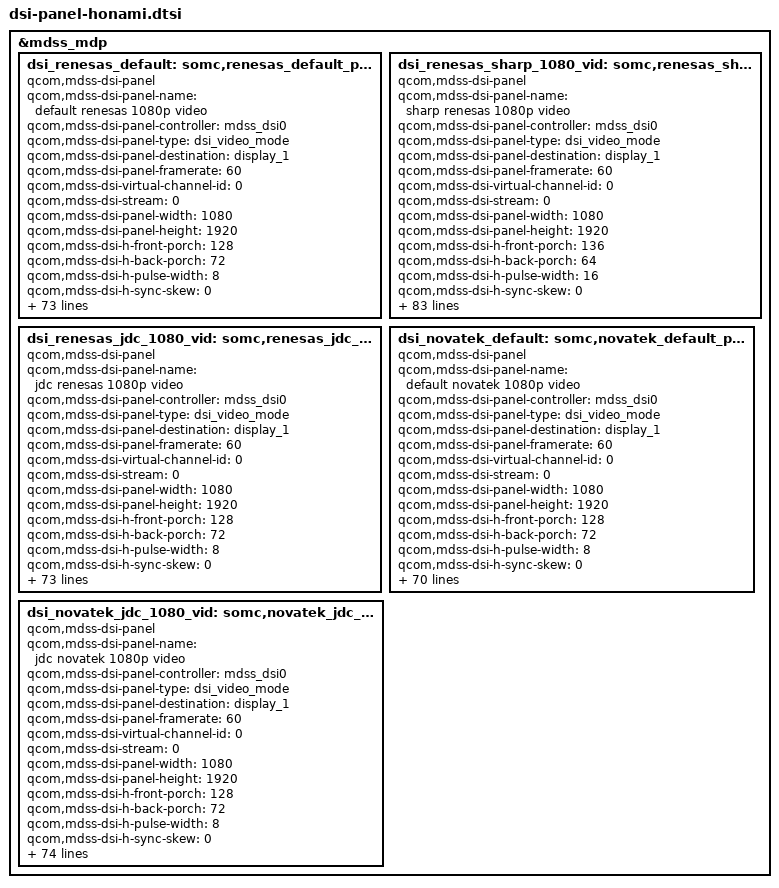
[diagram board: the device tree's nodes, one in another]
/* Copyright (c) 2012, Code Aurora Forum. All rights reserved.
 * Copyright (C) 2013-2014 Sony Mobile Communications AB.
 *
 * This program is free software; you can redistribute it and/or modify
 * it under the terms of the GNU General Public License version 2 and
 * only version 2 as published by the Free Software Foundation.
 *
 * This program is distributed in the hope that it will be useful,
 * but WITHOUT ANY WARRANTY; without even the implied warranty of
 * MERCHANTABILITY or FITNESS FOR A PARTICULAR PURPOSE.  See the
 * GNU General Public License for more details.
 */

&mdss_mdp {
	dsi_renesas_default: somc,renesas_default_panel {
		compatible = "qcom,mdss-dsi-panel";

		qcom,mdss-dsi-panel-name = "default renesas 1080p video";
		qcom,mdss-dsi-panel-controller = <&mdss_dsi0>;
		qcom,mdss-dsi-panel-type = "dsi_video_mode";
		qcom,mdss-dsi-panel-destination = "display_1";
		qcom,mdss-dsi-panel-framerate = <60>;
		qcom,mdss-dsi-virtual-channel-id = <0>;
		qcom,mdss-dsi-stream = <0>;
		qcom,mdss-dsi-panel-width = <1080>;
		qcom,mdss-dsi-panel-height = <1920>;
		qcom,mdss-dsi-h-front-porch = <128>;
		qcom,mdss-dsi-h-back-porch = <72>;
		qcom,mdss-dsi-h-pulse-width = <8>;
		qcom,mdss-dsi-h-sync-skew = <0>;
		qcom,mdss-dsi-v-back-porch = <4>;
		qcom,mdss-dsi-v-front-porch = <8>;
		qcom,mdss-dsi-v-pulse-width = <4>;
		qcom,mdss-dsi-h-left-border = <0>;
		qcom,mdss-dsi-h-right-border = <0>;
		qcom,mdss-dsi-v-top-border = <0>;
		qcom,mdss-dsi-v-bottom-border = <0>;
		qcom,mdss-dsi-bpp = <24>;
		qcom,mdss-dsi-underflow-color = <0x0>;
		qcom,mdss-dsi-border-color = <0>;
		somc,mdss-dsi-id-read-command = [06 01 00 01 05 00 02 A1 00];
		somc,mdss-dsi-init-command = [23 01 00 00 00 00 02 B0 00
				23 01 00 00 00 00 02 D6 01
				29 01 00 00 00 00 19 C7
					07 08 0B 12 22 3D 30 3D 52 54 68 78
					07 08 0B 12 22 3D 30 3D 52 54 68 78
				29 01 00 00 00 00 19 C8
					07 12 1A 25 32 45 33 3F 4F 50 5D 78
					07 12 1A 25 32 45 33 3F 4F 50 5D 78
				29 01 00 00 00 00 19 C9
					07 21 2B 33 3D 4C 35 40 51 53 5C 78
					07 21 2B 33 3D 4C 35 40 51 53 5C 78
				05 01 00 00 00 00 01 11];
		qcom,mdss-dsi-on-command = [05 01 00 00 00 00 01 29];
		qcom,mdss-dsi-off-command = [05 01 00 00 14 00 01 28
				05 01 00 00 50 00 01 10];
		qcom,mdss-dsi-on-command-state = "dsi_lp_mode";
		qcom,mdss-dsi-off-command-state = "dsi_hs_mode";

		somc,mdss-dsi-cabc-early-on-command = [39 01 00 00 00 00 03 51 0F FF
				15 01 00 00 00 00 02 53 24
				15 01 00 00 00 00 02 55 03];
		somc,mdss-dsi-cabc-early-on-v3-command = [39 01 00 00 00 00 03 51 0F FF
				15 01 00 00 00 00 02 53 24
				15 01 00 00 00 00 02 55 03];
		somc,mdss-dsi-cabc-late-off-command = [39 01 00 00 00 00 03 51 00 00
				15 01 00 00 00 00 02 55 00
				15 01 00 00 00 00 02 53 20];
		somc,mdss-dsi-cabc-deferred-on-command = [23 01 00 00 00 00 02 B0 00
				29 01 00 00 00 00 08 B9 00 3F 18 18 9F 1F 80
				29 01 00 00 00 00 08 BA 00 3F 04 40 9F 1F A8
				29 01 00 00 00 00 1A B8 18 80 18 18 CF 1F 00
					0C 0F 6C 0F 6C 0F 0C
					0F DA 6D FF FF 10 7D
					BC F7 FF FF
				23 01 00 00 00 00 02 B0 03];
		somc,mdss-dsi-cabc-deferred-on-v3-command = [23 01 00 00 00 00 02 B0 00
				29 01 00 00 00 00 08 B9 00 30 18 18 9F 1F 80
				29 01 00 00 00 00 08 BA 00 30 04 40 9F 1F CC
				29 01 00 00 00 00 1A B8 18 80 18 18 CF 1F 00
					0C 14 6C 14 6C 15 0C
					14 DA 6D FF FF 10 4D
					81 BB E7 FF
				23 01 00 00 00 00 02 B0 03];
		somc,mdss-dsi-cabc-enabled = <1>;

		qcom,mdss-dsi-h-sync-pulse = <1>;
		qcom,mdss-dsi-traffic-mode = "non_burst_sync_event";
		qcom,mdss-dsi-bllp-eof-power-mode;
		qcom,mdss-dsi-bllp-power-mode;
		qcom,mdss-dsi-lane-0-state;
		qcom,mdss-dsi-lane-1-state;
		qcom,mdss-dsi-lane-2-state;
		qcom,mdss-dsi-lane-3-state;
		qcom,mdss-dsi-panel-timings = [da 46 39 00 5f 56 3c 48 5d 03 04 00];
		qcom,mdss-dsi-t-clk-post = <0x20>;
		qcom,mdss-dsi-t-clk-pre = <0x2a>;
		qcom,mdss-dsi-bl-min-level = <1>;
		qcom,mdss-dsi-bl-max-level = <4095>;
		qcom,mdss-dsi-dma-trigger = "trigger_sw";
		qcom,mdss-dsi-mdp-trigger = "none";
		qcom,mdss-dsi-bl-pmic-control-type = "bl_ctrl_wled";
		qcom,mdss-dsi-pan-enable-dynamic-fps;
		qcom,mdss-dsi-pan-fps-update = "dfps_suspend_resume_mode";
		qcom,mdss-dsi-reset-sequence = <1 20>, <0 200>, <1 20>;

		somc,panel-id = [ff];
		somc,panel-detect = <1>;
		somc,driver-ic = <0>;
		somc,panel-id-read-cmds;
		somc,dsi-restart-hack;
		qcom,mdss-pan-physical-width-dimension = <62>;
		qcom,mdss-pan-physical-height-dimension = <110>;
		somc,mdss-phy-size-mm = <62 110>;
		somc,mdss-dsi-lane-config = [00 c2 45 00 00 00 00 01 75
				00 c2 45 00 00 00 00 01 75
				00 c2 45 00 00 00 00 01 75
				00 c2 45 00 00 00 00 01 75
				00 02 45 00 00 00 00 01 97];
		somc,mdss-dsi-disp-on-in-hs = <1>;
		somc,mdss-dsi-wait-time-before-on-cmd = <120>;
		qcom,mdss-brightness-max-level = <255>;
		somc,disp-en-off-pre = <10>;
		somc,disp-en-off-post = <10>;
		somc,disp-en-on-pre = <25>;
		somc,pw-on-rst-seq = <0 10>, <1 10>;
		somc,pw-off-rst-seq = <0 10>;
	};

	dsi_renesas_sharp_1080_vid: somc,renesas_sharp_1080p_panel {
		compatible = "qcom,mdss-dsi-panel";

		qcom,mdss-dsi-panel-name = "sharp renesas 1080p video";
		qcom,mdss-dsi-panel-controller = <&mdss_dsi0>;
		qcom,mdss-dsi-panel-type = "dsi_video_mode";
		qcom,mdss-dsi-panel-destination = "display_1";
		qcom,mdss-dsi-panel-framerate = <60>;
		qcom,mdss-dsi-virtual-channel-id = <0>;
		qcom,mdss-dsi-stream = <0>;
		qcom,mdss-dsi-panel-width = <1080>;
		qcom,mdss-dsi-panel-height = <1920>;
		qcom,mdss-dsi-h-front-porch = <136>;
		qcom,mdss-dsi-h-back-porch = <64>;
		qcom,mdss-dsi-h-pulse-width = <16>;
		qcom,mdss-dsi-h-sync-skew = <0>;
		qcom,mdss-dsi-v-back-porch = <3>;
		qcom,mdss-dsi-v-front-porch = <2>;
		qcom,mdss-dsi-v-pulse-width = <2>;
		qcom,mdss-dsi-h-left-border = <0>;
		qcom,mdss-dsi-h-right-border = <0>;
		qcom,mdss-dsi-v-top-border = <0>;
		qcom,mdss-dsi-v-bottom-border = <0>;
		qcom,mdss-dsi-bpp = <24>;
		qcom,mdss-dsi-underflow-color = <0x0>;
		qcom,mdss-dsi-border-color = <0>;
		somc,mdss-dsi-id-read-command = [06 01 00 01 05 00 02 A1 00];
		somc,mdss-dsi-init-command = [29 01 00 00 00 00 02 B0 04
				05 01 00 00 00 00 02 00 00
				05 01 00 00 00 00 02 00 00
				29 01 00 00 00 00 19 C7
					0F 13 17 1D 28 3C 2A 3E 4E 5E 6D 75
					0F 14 18 1E 2A 3E 2D 42 53 63 71 78
				29 01 00 00 00 00 19 C8
					20 23 26 2B 32 43 2D 3F 4F 5D 6C 75
					22 25 28 2D 34 46 30 43 54 62 70 78
				29 01 00 00 00 00 19 C9
					1A 22 27 2D 37 48 31 41 52 62 6F 75
					1B 23 28 2F 39 4B 35 46 57 66 73 78
				29 01 00 00 00 00 08 C2 30 F7 80 05 08 00 00
				29 01 00 00 00 00 02 D6 01
				05 01 00 00 00 00 01 11];
		qcom,mdss-dsi-on-command = [05 01 00 00 00 00 01 29];
		qcom,mdss-dsi-off-command = [05 01 00 00 14 00 01 28
				05 01 00 00 64 00 01 10];
		qcom,mdss-dsi-on-command-state = "dsi_lp_mode";
		qcom,mdss-dsi-off-command-state = "dsi_hs_mode";

		somc,mdss-dsi-cabc-early-on-command = [39 01 00 00 00 00 03 51 0F FF
				15 01 00 00 00 00 02 53 24
				15 01 00 00 00 00 02 55 03];
		somc,mdss-dsi-cabc-early-on-v3-command = [39 01 00 00 00 00 03 51 0F FF
				15 01 00 00 00 00 02 53 24
				15 01 00 00 00 00 02 55 03];
		somc,mdss-dsi-cabc-late-off-command = [39 01 00 00 00 00 03 51 00 00
				15 01 00 00 00 00 02 55 00
				15 01 00 00 00 00 02 53 20];
		somc,mdss-dsi-cabc-deferred-on-command = [23 01 00 00 00 00 02 B0 00
				29 01 00 00 00 00 08 B9 00 3F 18 18 9F 1F 80
				29 01 00 00 00 00 08 BA 00 3F 04 40 9F 1F A8
				29 01 00 00 00 00 1A B8 18 80 18 18 CF 1F 00
					0C 0F 6C 0F 6C 0F 0C
					0F DA 6D FF FF 10 7D
					BC F7 FF FF
				23 01 00 00 00 00 02 B0 03];
		somc,mdss-dsi-cabc-deferred-on-v3-command = [23 01 00 00 00 00 02 B0 00
				29 01 00 00 00 00 08 B9 00 30 18 18 9F 1F 80
				29 01 00 00 00 00 08 BA 00 30 04 40 9F 1F CC
				29 01 00 00 00 00 1A B8 18 80 18 18 CF 1F 00
					0C 14 6C 14 6C 15 0C
					14 DA 6D FF FF 10 4D
					81 BB E7 FF
				23 01 00 00 00 00 02 B0 03];
		somc,mdss-dsi-cabc-enabled = <1>;

		qcom,mdss-dsi-h-sync-pulse = <1>;
		qcom,mdss-dsi-traffic-mode = "non_burst_sync_event";
		qcom,mdss-dsi-bllp-eof-power-mode;
		qcom,mdss-dsi-bllp-power-mode;
		qcom,mdss-dsi-lane-0-state;
		qcom,mdss-dsi-lane-1-state;
		qcom,mdss-dsi-lane-2-state;
		qcom,mdss-dsi-lane-3-state;
		qcom,mdss-dsi-panel-timings = [EA 38 25 00 67 6F 29 3C 5D 03 04 00];
		qcom,mdss-dsi-t-clk-post = <0x03>;
		qcom,mdss-dsi-t-clk-pre = <0x31>;
		qcom,mdss-dsi-bl-min-level = <1>;
		qcom,mdss-dsi-bl-max-level = <4095>;
		qcom,mdss-dsi-dma-trigger = "trigger_sw";
		qcom,mdss-dsi-mdp-trigger = "none";
		qcom,mdss-dsi-bl-pmic-control-type = "bl_ctrl_wled";
		qcom,mdss-dsi-pan-enable-dynamic-fps;
		qcom,mdss-dsi-pan-fps-update = "dfps_suspend_resume_mode";
		qcom,mdss-dsi-reset-sequence = <1 20>, <0 200>, <1 20>;

		somc,panel-id = [ff ff ff 63];
		somc,driver-ic = <0>;
		qcom,mdss-pan-physical-width-dimension = <62>;
		qcom,mdss-pan-physical-height-dimension = <110>;
		somc,mdss-phy-size-mm = <62 110>;
		somc,mdss-dsi-lane-config = [00 c2 45 00 00 00 00 01 75
				00 c2 45 00 00 00 00 01 75
				00 c2 45 00 00 00 00 01 75
				00 c2 45 00 00 00 00 01 75
				00 02 45 00 00 00 00 01 97];
		somc,mdss-dsi-disp-on-in-hs = <1>;
		somc,mdss-dsi-wait-time-before-on-cmd = <150>;
		qcom,mdss-brightness-max-level = <255>;
		somc,disp-en-off-pre = <10>;
		somc,disp-en-off-post = <10>;
		somc,disp-en-on-pre = <25>;
		somc,pw-on-rst-seq = <0 10>, <1 10>;
		somc,pw-off-rst-seq = <0 10>;

		somc,mdss-dsi-pre-uv-command = [29 01 00 00 00 00 02 B0 04];
		somc,mdss-dsi-uv-command = [04 01 00 00 00 00 01 EF];
		somc,mdss-dsi-uv-param-type = <1>;
		somc,mdss-dsi-pcc-table-size = <73>;
		somc,mdss-dsi-pcc-table = <
				0x00 0x01 0x10 0x13 0x28 0x2B 0x8000 0x7400 0x8000
				0x00 0x02 0x14 0x17 0x28 0x2B 0x7a80 0x7400 0x7e00
				0x00 0x03 0x18 0x1B 0x28 0x2B 0x7480 0x7380 0x8000
				0x00 0x04 0x1C 0x1F 0x28 0x2B 0x7280 0x7380 0x8000
				0x00 0x05 0x20 0x23 0x28 0x2B 0x6e00 0x7400 0x8000
				0x00 0x06 0x0C 0x0F 0x24 0x27 0x7f80 0x7200 0x7c00
				0x00 0x07 0x10 0x13 0x24 0x27 0x8000 0x7400 0x7d80
				0x00 0x08 0x14 0x17 0x24 0x27 0x7d00 0x7700 0x7e00
				0x00 0x09 0x18 0x1B 0x24 0x27 0x7700 0x7600 0x8000
				0x00 0x0A 0x1C 0x1F 0x24 0x27 0x7380 0x7500 0x7c00
				0x00 0x0B 0x20 0x23 0x24 0x27 0x6f00 0x7500 0x7e80
				0x00 0x0C 0x0C 0x0F 0x20 0x23 0x7f80 0x7200 0x7900
				0x00 0x0D 0x10 0x13 0x20 0x23 0x8000 0x7400 0x7b00
				0x00 0x0E 0x14 0x17 0x20 0x23 0x7a80 0x7400 0x7b00
				0x00 0x0F 0x18 0x1B 0x20 0x23 0x7800 0x7700 0x7e80
				0x00 0x10 0x1C 0x1F 0x20 0x23 0x7780 0x7900 0x7f80
				0x00 0x11 0x20 0x23 0x20 0x23 0x7300 0x7900 0x7f00
				0x00 0x12 0x24 0x27 0x20 0x23 0x7100 0x7980 0x8000
				0x00 0x13 0x0C 0x0F 0x1C 0x1F 0x7f80 0x7200 0x7700
				0x00 0x14 0x10 0x13 0x1C 0x1F 0x7c00 0x7000 0x7580
				0x00 0x15 0x14 0x17 0x1C 0x1F 0x7f80 0x7900 0x7e00
				0x00 0x16 0x18 0x1B 0x1C 0x1F 0x7c00 0x7a00 0x7d80
				0x00 0x17 0x1C 0x1F 0x1C 0x1F 0x7900 0x7a00 0x7e00
				0x00 0x18 0x20 0x23 0x1C 0x1F 0x7600 0x7c80 0x8000
				0x00 0x19 0x24 0x27 0x1C 0x1F 0x7300 0x7c00 0x7e80
				0x00 0x1A 0x0C 0x0F 0x18 0x1B 0x8000 0x7200 0x7300
				0x00 0x1B 0x10 0x13 0x18 0x1B 0x7e80 0x7200 0x7500
				0x00 0x1C 0x14 0x17 0x18 0x1B 0x7f00 0x7900 0x7b80
				0x00 0x1D 0x18 0x1B 0x18 0x1B 0x7f00 0x7d00 0x7e00
				0x00 0x1E 0x1C 0x1F 0x18 0x1B 0x7d00 0x7d80 0x8000
				0x00 0x1F 0x20 0x23 0x18 0x1B 0x7900 0x7f00 0x8000
				0x00 0x20 0x24 0x27 0x18 0x1B 0x7780 0x8000 0x8000
				0x00 0x21 0x10 0x13 0x14 0x17 0x7f80 0x7380 0x7200
				0x00 0x22 0x14 0x17 0x14 0x17 0x7f00 0x7900 0x7900
				0x00 0x23 0x18 0x1B 0x14 0x17 0x7f00 0x7d00 0x7b80
				0xFF 0x00 0x1C 0x1F 0x14 0x17 0x8000 0x8000 0x8000
				0x00 0x24 0x20 0x23 0x14 0x17 0x7a00 0x8000 0x7e80
				0x00 0x25 0x24 0x27 0x14 0x17 0x7780 0x8000 0x7d80
				0x00 0x26 0x10 0x13 0x10 0x13 0x8000 0x7400 0x7000
				0x00 0x27 0x14 0x17 0x10 0x13 0x7f80 0x7900 0x7680
				0x00 0x28 0x18 0x1B 0x10 0x13 0x8000 0x7d80 0x7980
				0x00 0x29 0x1C 0x1F 0x10 0x13 0x8000 0x8000 0x7c00
				0x00 0x2A 0x20 0x23 0x10 0x13 0x7a00 0x8000 0x7c00
				0x00 0x2B 0x10 0x13 0x0C 0x0F 0x7f80 0x7480 0x6f00
				0x00 0x2C 0x14 0x17 0x0C 0x0F 0x7f80 0x7900 0x7400
				0x00 0x2D 0x18 0x1B 0x0C 0x0F 0x7f80 0x7d80 0x7680
				0x00 0x2E 0x1C 0x1F 0x0C 0x0F 0x7C00 0x7C00 0x8000
				0x01 0x00 0x00 0x09 0x32 0x3B 0x8000 0x6D00 0x8000
				0x02 0x00 0x0A 0x13 0x32 0x3B 0x7A00 0x7100 0x8000
				0x03 0x00 0x14 0x1D 0x32 0x3B 0x7400 0x7180 0x8000
				0x04 0x00 0x1E 0x27 0x32 0x3B 0x7100 0x7200 0x8000
				0x05 0x00 0x28 0x31 0x32 0x3B 0x6C80 0x7180 0x8000
				0x06 0x00 0x32 0x3B 0x32 0x3B 0x6680 0x7300 0x8000
				0x07 0x00 0x00 0x09 0x28 0x31 0x8000 0x6B80 0x7080
				0x08 0x00 0x0A 0x13 0x28 0x31 0x8000 0x7400 0x8000
				0x09 0x00 0x14 0x1D 0x28 0x31 0x7A00 0x7700 0x8000
				0x0A 0x00 0x1E 0x27 0x28 0x31 0x7600 0x7780 0x8000
				0x0B 0x00 0x28 0x31 0x28 0x31 0x6F80 0x7980 0x8000
				0x0C 0x00 0x32 0x3B 0x28 0x31 0x7080 0x7E80 0x8000
				0x0D 0x00 0x00 0x09 0x14 0x27 0x8000 0x6B00 0x6D00
				0x0E 0x00 0x0A 0x13 0x14 0x27 0x8000 0x7380 0x7480
				0xFF 0x00 0x14 0x27 0x14 0x27 0x8000 0x8000 0x8000
				0x10 0x00 0x28 0x31 0x14 0x27 0x7500 0x8000 0x7E80
				0x11 0x00 0x32 0x3B 0x14 0x27 0x7100 0x8000 0x7C80
				0x12 0x00 0x00 0x09 0x00 0x09 0x8000 0x6900 0x6500
				0x13 0x00 0x00 0x13 0x0A 0x13 0x8000 0x7300 0x6F00
				0x13 0x00 0x0A 0x13 0x00 0x09 0x8000 0x7300 0x6F00
				0x14 0x00 0x14 0x27 0x0A 0x13 0x7F00 0x8000 0x7900
				0x15 0x00 0x14 0x27 0x00 0x09 0x7E80 0x8000 0x7680
				0x16 0x00 0x28 0x31 0x0A 0x13 0x7380 0x8000 0x7600
				0x17 0x00 0x32 0x3B 0x0A 0x13 0x7080 0x8000 0x7900
				0x18 0x00 0x28 0x31 0x00 0x09 0x7A00 0x8000 0x7580
				0x19 0x00 0x32 0x3B 0x00 0x09 0x6F00 0x8000 0x7200>;
		somc,mdss-dsi-use-picadj = <1>;
		somc,mdss-dsi-picadj-sat = <6674>;
		somc,mdss-dsi-picadj-hue = <0>;
		somc,mdss-dsi-picadj-val = <0>;
		somc,mdss-dsi-picadj-cont = <9>;
	};

	dsi_renesas_jdc_1080_vid: somc,renesas_jdc_1080p_panel {
		compatible = "qcom,mdss-dsi-panel";

		qcom,mdss-dsi-panel-name = "jdc renesas 1080p video";
		qcom,mdss-dsi-panel-controller = <&mdss_dsi0>;
		qcom,mdss-dsi-panel-type = "dsi_video_mode";
		qcom,mdss-dsi-panel-destination = "display_1";
		qcom,mdss-dsi-panel-framerate = <60>;
		qcom,mdss-dsi-virtual-channel-id = <0>;
		qcom,mdss-dsi-stream = <0>;
		qcom,mdss-dsi-panel-width = <1080>;
		qcom,mdss-dsi-panel-height = <1920>;
		qcom,mdss-dsi-h-front-porch = <128>;
		qcom,mdss-dsi-h-back-porch = <72>;
		qcom,mdss-dsi-h-pulse-width = <8>;
		qcom,mdss-dsi-h-sync-skew = <0>;
		qcom,mdss-dsi-v-back-porch = <4>;
		qcom,mdss-dsi-v-front-porch = <8>;
		qcom,mdss-dsi-v-pulse-width = <4>;
		qcom,mdss-dsi-h-left-border = <0>;
		qcom,mdss-dsi-h-right-border = <0>;
		qcom,mdss-dsi-v-top-border = <0>;
		qcom,mdss-dsi-v-bottom-border = <0>;
		qcom,mdss-dsi-bpp = <24>;
		qcom,mdss-dsi-underflow-color = <0x0>;
		qcom,mdss-dsi-border-color = <0>;
		somc,mdss-dsi-id-read-command = [06 01 00 01 05 00 02 A1 00];
		somc,mdss-dsi-init-command = [23 01 00 00 00 00 02 B0 00
				23 01 00 00 00 00 02 D6 01
				29 01 00 00 00 00 19 C7
					07 08 0B 12 22 3D 30 3D 52 54 68 78
					07 08 0B 12 22 3D 30 3D 52 54 68 78
				29 01 00 00 00 00 19 C8
					07 12 1A 25 32 45 33 3F 4F 50 5D 78
					07 12 1A 25 32 45 33 3F 4F 50 5D 78
				29 01 00 00 00 00 19 C9
					07 21 2B 33 3D 4C 35 40 51 53 5C 78
					07 21 2B 33 3D 4C 35 40 51 53 5C 78
				05 01 00 00 00 00 01 11];
		qcom,mdss-dsi-on-command = [05 01 00 00 00 00 01 29];
		qcom,mdss-dsi-off-command = [05 01 00 00 14 00 01 28
				05 01 00 00 50 00 01 10];
		qcom,mdss-dsi-on-command-state = "dsi_lp_mode";
		qcom,mdss-dsi-off-command-state = "dsi_hs_mode";

		somc,mdss-dsi-cabc-early-on-command = [39 01 00 00 00 00 03 51 0F FF
				15 01 00 00 00 00 02 53 24
				15 01 00 00 00 00 02 55 03];
		somc,mdss-dsi-cabc-early-on-v3-command = [39 01 00 00 00 00 03 51 0F FF
				15 01 00 00 00 00 02 53 24
				15 01 00 00 00 00 02 55 03];
		somc,mdss-dsi-cabc-late-off-command = [39 01 00 00 00 00 03 51 00 00
				15 01 00 00 00 00 02 55 00
				15 01 00 00 00 00 02 53 20];
		somc,mdss-dsi-cabc-deferred-on-command = [23 01 00 00 00 00 02 B0 00
				29 01 00 00 00 00 08 B9 00 3F 18 18 9F 1F 80
				29 01 00 00 00 00 08 BA 00 3F 04 40 9F 1F A8
				29 01 00 00 00 00 1A B8 18 80 18 18 CF 1F 00
					0C 0F 6C 0F 6C 0F 0C
					0F DA 6D FF FF 10 7D
					BC F7 FF FF
				23 01 00 00 00 00 02 B0 03];
		somc,mdss-dsi-cabc-deferred-on-v3-command = [23 01 00 00 00 00 02 B0 00
				29 01 00 00 00 00 08 B9 00 30 18 18 9F 1F 80
				29 01 00 00 00 00 08 BA 00 30 04 40 9F 1F CC
				29 01 00 00 00 00 1A B8 18 80 18 18 CF 1F 00
					0C 14 6C 14 6C 15 0C
					14 DA 6D FF FF 10 4D
					81 BB E7 FF
				23 01 00 00 00 00 02 B0 03];
		somc,mdss-dsi-cabc-enabled = <1>;

		qcom,mdss-dsi-h-sync-pulse = <1>;
		qcom,mdss-dsi-traffic-mode = "non_burst_sync_event";
		qcom,mdss-dsi-bllp-eof-power-mode;
		qcom,mdss-dsi-bllp-power-mode;
		qcom,mdss-dsi-lane-0-state;
		qcom,mdss-dsi-lane-1-state;
		qcom,mdss-dsi-lane-2-state;
		qcom,mdss-dsi-lane-3-state;
		qcom,mdss-dsi-panel-timings = [da 46 39 00 5f 56 3c 48 5d 03 04 00];
		qcom,mdss-dsi-t-clk-post = <0x20>;
		qcom,mdss-dsi-t-clk-pre = <0x2a>;
		qcom,mdss-dsi-bl-min-level = <1>;
		qcom,mdss-dsi-bl-max-level = <4095>;
		qcom,mdss-dsi-dma-trigger = "trigger_sw";
		qcom,mdss-dsi-mdp-trigger = "none";
		qcom,mdss-dsi-bl-pmic-control-type = "bl_ctrl_wled";
		qcom,mdss-dsi-pan-enable-dynamic-fps;
		qcom,mdss-dsi-pan-fps-update = "dfps_suspend_resume_mode";
		qcom,mdss-dsi-reset-sequence = <1 20>, <0 200>, <1 20>;

		somc,panel-id = [ff ff ff 62];
		somc,driver-ic = <0>;
		qcom,mdss-pan-physical-width-dimension = <62>;
		qcom,mdss-pan-physical-height-dimension = <110>;
		somc,mdss-phy-size-mm = <62 110>;
		somc,mdss-dsi-lane-config = [00 c2 45 00 00 00 00 01 75
				00 c2 45 00 00 00 00 01 75
				00 c2 45 00 00 00 00 01 75
				00 c2 45 00 00 00 00 01 75
				00 02 45 00 00 00 00 01 97];
		somc,mdss-dsi-disp-on-in-hs = <1>;
		qcom,mdss-brightness-max-level = <255>;
		somc,mdss-dsi-wait-time-before-on-cmd = <120>;

		somc,mdss-dsi-pre-uv-command = [29 01 00 00 00 00 02 B0 04];
		somc,mdss-dsi-uv-command = [04 01 00 00 00 00 01 EF];
		somc,mdss-dsi-uv-param-type = <1>;
		somc,mdss-dsi-pcc-table-size = <78>;
		somc,mdss-dsi-pcc-table = <
				0x00 0x01 0x26 0x29 0x38 0x3C 0x5FA9 0x7760 0x8000
				0x00 0x02 0x22 0x25 0x34 0x37 0x67BF 0x7988 0x8000
				0x00 0x03 0x26 0x29 0x34 0x37 0x67BF 0x7988 0x8000
				0x00 0x04 0x1F 0x22 0x30 0x33 0x6CCC 0x7AE1 0x8000
				0x00 0x05 0x23 0x26 0x30 0x33 0x6CCC 0x7AE1 0x8000
				0x00 0x06 0x27 0x2A 0x30 0x33 0x6CCC 0x7AE1 0x8000
				0x00 0x07 0x1C 0x1F 0x2C 0x2F 0x79EF 0x7E62 0x8000
				0x00 0x08 0x20 0x23 0x2C 0x2F 0x79EF 0x7E62 0x8000
				0x00 0x09 0x24 0x27 0x2C 0x2F 0x79EF 0x7E62 0x8000
				0x00 0x0A 0x28 0x2B 0x2C 0x2F 0x79EF 0x7E62 0x8000
				0x00 0x0B 0x1A 0x1D 0x28 0x2B 0x8000 0x8000 0x8000
				0x00 0x0C 0x1E 0x21 0x28 0x2B 0x8000 0x8000 0x8000
				0x00 0x0D 0x22 0x25 0x28 0x2B 0x8000 0x8000 0x8000
				0x00 0x0E 0x26 0x29 0x28 0x2B 0x8000 0x8000 0x8000
				0x00 0x0F 0x18 0x1B 0x24 0x27 0x7f00 0x7880 0x8000
				0x00 0x10 0x1C 0x1F 0x24 0x27 0x7980 0x7900 0x8000
				0x00 0x11 0x20 0x23 0x24 0x27 0x7500 0x7980 0x8000
				0x00 0x12 0x24 0x27 0x24 0x27 0x7000 0x7a00 0x8000
				0x00 0x13 0x28 0x29 0x24 0x27 0x6d00 0x7a80 0x8000
				0x00 0x14 0x16 0x17 0x20 0x23 0x8000 0x7500 0x7900
				0x00 0x15 0x18 0x1B 0x20 0x23 0x8000 0x7900 0x7d00
				0x00 0x16 0x1C 0x1F 0x20 0x23 0x7c00 0x7b80 0x7f00
				0x00 0x17 0x20 0x23 0x20 0x23 0x7200 0x7780 0x7980
				0x00 0x18 0x24 0x27 0x20 0x23 0x7100 0x7c00 0x7e00
				0x00 0x19 0x28 0x29 0x20 0x23 0x6f00 0x7d80 0x7f00
				0x00 0x1A 0x16 0x17 0x1C 0x1F 0x8000 0x7500 0x7600
				0x00 0x1B 0x18 0x1B 0x1C 0x1F 0x8000 0x7980 0x7a00
				0xFF 0x00 0x1C 0x1F 0x1C 0x1F 0x8000 0x8000 0x8000
				0x00 0x1C 0x20 0x23 0x1C 0x1F 0x7900 0x8000 0x7e80
				0x00 0x1D 0x24 0x27 0x1C 0x1F 0x7400 0x8000 0x7e00
				0x00 0x1E 0x28 0x29 0x1C 0x1F 0x7000 0x8000 0x7d80
				0x00 0x1F 0x16 0x17 0x18 0x1B 0x8000 0x7500 0x7280
				0x00 0x20 0x18 0x1B 0x18 0x1B 0x8000 0x7a00 0x7600
				0x00 0x21 0x1C 0x1F 0x18 0x1B 0x7e80 0x8000 0x7b80
				0x00 0x22 0x20 0x23 0x18 0x1B 0x7900 0x8000 0x7b00
				0x00 0x23 0x24 0x27 0x18 0x1B 0x7400 0x8000 0x7a00
				0x00 0x24 0x28 0x29 0x18 0x1B 0x7000 0x8000 0x7a00
				0x00 0x25 0x16 0x19 0x14 0x17 0x8000 0x7780 0x7000
				0x00 0x26 0x1A 0x1D 0x14 0x17 0x8000 0x7e00 0x7500
				0x00 0x27 0x1E 0x21 0x14 0x17 0x7b00 0x8000 0x7500
				0x00 0x28 0x22 0x25 0x14 0x17 0x7580 0x8000 0x7600
				0x00 0x29 0x16 0x19 0x10 0x13 0x8000 0x7900 0x6c80
				0x00 0x2A 0x1A 0x1D 0x10 0x13 0x8000 0x7f00 0x7200
				0x00 0x2B 0x1E 0x21 0x10 0x13 0x7a00 0x8000 0x7180
				0x00 0x2C 0x22 0x25 0x10 0x13 0x7500 0x8000 0x7200
				0x00 0x2D 0x16 0x19 0x0C 0x0F 0x8000 0x7900 0x6a00
				0x00 0x2E 0x1A 0x1D 0x0C 0x0F 0x8000 0x8000 0x6f00
				0x00 0x2F 0x1E 0x21 0x0C 0x0F 0x7980 0x8000 0x6e00
				0x00 0x30 0x16 0x19 0x08 0x0B 0x8000 0x7900 0x6800
				0x00 0x31 0x1A 0x1D 0x08 0x0B 0x8000 0x8000 0x6c00
				0x00 0x32 0x16 0x19 0x04 0x07 0x8000 0x7880 0x6580
				0x00 0x33 0x26 0x29 0x14 0x17 0x7580 0x8000 0x7600
				0x01 0x00 0x00 0x09 0x32 0x3C 0x8000 0x6D00 0x8000
				0x02 0x00 0x0A 0x13 0x32 0x3C 0x7A00 0x7100 0x8000
				0x03 0x00 0x14 0x1D 0x32 0x3C 0x7400 0x7180 0x8000
				0x04 0x00 0x1E 0x27 0x32 0x3C 0x7100 0x7200 0x8000
				0x05 0x00 0x28 0x31 0x32 0x3C 0x6C80 0x7180 0x8000
				0x06 0x00 0x32 0x3C 0x32 0x3C 0x6680 0x7300 0x8000
				0x07 0x00 0x00 0x09 0x28 0x31 0x8000 0x6B80 0x7080
				0x08 0x00 0x0A 0x13 0x28 0x31 0x8000 0x7400 0x8000
				0x09 0x00 0x14 0x1D 0x28 0x31 0x7A00 0x7700 0x8000
				0x0A 0x00 0x1E 0x27 0x28 0x31 0x7600 0x7780 0x8000
				0x0B 0x00 0x28 0x31 0x28 0x31 0x6F80 0x7980 0x8000
				0x0C 0x00 0x32 0x3C 0x28 0x31 0x7080 0x7E80 0x8000
				0x0D 0x00 0x00 0x09 0x14 0x27 0x8000 0x6B00 0x6D00
				0x0E 0x00 0x0A 0x13 0x14 0x27 0x8000 0x7380 0x7480
				0xFF 0x00 0x14 0x27 0x14 0x27 0x8000 0x8000 0x8000
				0x10 0x00 0x28 0x31 0x14 0x27 0x7500 0x8000 0x7E80
				0x11 0x00 0x32 0x3C 0x14 0x27 0x7100 0x8000 0x7C80
				0x12 0x00 0x00 0x09 0x00 0x09 0x8000 0x6900 0x6500
				0x13 0x00 0x00 0x13 0x0A 0x13 0x8000 0x7300 0x6F00
				0x13 0x00 0x0A 0x13 0x00 0x09 0x8000 0x7300 0x6F00
				0x14 0x00 0x14 0x27 0x0A 0x13 0x7F00 0x8000 0x7900
				0x15 0x00 0x14 0x27 0x00 0x09 0x7E80 0x8000 0x7680
				0x16 0x00 0x28 0x31 0x0A 0x13 0x7380 0x8000 0x7600
				0x17 0x00 0x32 0x3C 0x0A 0x13 0x7080 0x8000 0x7900
				0x18 0x00 0x28 0x31 0x00 0x09 0x7A00 0x8000 0x7580
				0x19 0x00 0x32 0x3C 0x00 0x09 0x6F00 0x8000 0x7200>;
	};

	dsi_novatek_default: somc,novatek_default_panel {
		compatible = "qcom,mdss-dsi-panel";

		qcom,mdss-dsi-panel-name = "default novatek 1080p video";
		qcom,mdss-dsi-panel-controller = <&mdss_dsi0>;
		qcom,mdss-dsi-panel-type = "dsi_video_mode";
		qcom,mdss-dsi-panel-destination = "display_1";
		qcom,mdss-dsi-panel-framerate = <60>;
		qcom,mdss-dsi-virtual-channel-id = <0>;
		qcom,mdss-dsi-stream = <0>;
		qcom,mdss-dsi-panel-width = <1080>;
		qcom,mdss-dsi-panel-height = <1920>;
		qcom,mdss-dsi-h-front-porch = <128>;
		qcom,mdss-dsi-h-back-porch = <72>;
		qcom,mdss-dsi-h-pulse-width = <8>;
		qcom,mdss-dsi-h-sync-skew = <0>;
		qcom,mdss-dsi-v-back-porch = <4>;
		qcom,mdss-dsi-v-front-porch = <8>;
		qcom,mdss-dsi-v-pulse-width = <4>;
		qcom,mdss-dsi-h-left-border = <0>;
		qcom,mdss-dsi-h-right-border = <0>;
		qcom,mdss-dsi-v-top-border = <0>;
		qcom,mdss-dsi-v-bottom-border = <0>;
		qcom,mdss-dsi-bpp = <24>;
		qcom,mdss-dsi-underflow-color = <0x0>;
		qcom,mdss-dsi-border-color = <0>;
		somc,mdss-dsi-id-read-command = [06 01 00 01 05 00 02 A1 00];
		somc,mdss-dsi-init-command = [
				15 01 00 00 00 00 02 36 00
				15 01 00 00 00 00 02 D3 08
				15 01 00 00 00 00 02 D4 08
				15 01 00 00 00 00 02 D5 50
				15 01 00 00 00 00 02 D6 81
				13 01 00 00 00 00 02 FF 01
				13 01 00 00 00 00 02 FB 01
				13 01 00 00 00 00 02 75 00
				13 01 00 00 00 00 02 76 00
				13 01 00 00 00 00 02 77 00
				13 01 00 00 00 00 02 78 03
				13 01 00 00 00 00 02 79 00
				13 01 00 00 00 00 02 7A 0A
				13 01 00 00 00 00 02 7B 00
				13 01 00 00 00 00 02 7C 13
				13 01 00 00 00 00 02 7D 00
				13 01 00 00 00 00 02 7E 20
				13 01 00 00 00 00 02 7F 00
				13 01 00 00 00 00 02 80 2E
				13 01 00 00 00 00 02 81 00
				13 01 00 00 00 00 02 82 3C
				13 01 00 00 00 00 02 83 00
				13 01 00 00 00 00 02 84 47
				13 01 00 00 00 00 02 85 00
				13 01 00 00 00 00 02 86 52
				13 01 00 00 00 00 02 87 00
				13 01 00 00 00 00 02 88 8E
				13 01 00 00 00 00 02 89 00
				13 01 00 00 00 00 02 8A B8
				13 01 00 00 00 00 02 8B 01
				13 01 00 00 00 00 02 8C 01
				13 01 00 00 00 00 02 8D 01
				13 01 00 00 00 00 02 8E 3A
				13 01 00 00 00 00 02 8F 01
				13 01 00 00 00 00 02 90 7E
				13 01 00 00 00 00 02 91 01
				13 01 00 00 00 00 02 92 B2
				13 01 00 00 00 00 02 93 01
				13 01 00 00 00 00 02 94 B4
				13 01 00 00 00 00 02 95 01
				13 01 00 00 00 00 02 96 E8
				13 01 00 00 00 00 02 97 02
				13 01 00 00 00 00 02 98 18
				13 01 00 00 00 00 02 99 02
				13 01 00 00 00 00 02 9A 36
				13 01 00 00 00 00 02 9B 02
				13 01 00 00 00 00 02 9C 5C
				13 01 00 00 00 00 02 9D 02
				13 01 00 00 00 00 02 9E 93
				13 01 00 00 00 00 02 9F 02
				13 01 00 00 00 00 02 A0 E1
				13 01 00 00 00 00 02 A2 02
				13 01 00 00 00 00 02 A3 E4
				13 01 00 00 00 00 02 A4 02
				13 01 00 00 00 00 02 A5 E8
				13 01 00 00 00 00 02 A6 02
				13 01 00 00 00 00 02 A7 EC
				13 01 00 00 00 00 02 A9 03
				13 01 00 00 00 00 02 AA 09
				13 01 00 00 00 00 02 AB 03
				13 01 00 00 00 00 02 AC 49
				13 01 00 00 00 00 02 AD 03
				13 01 00 00 00 00 02 AE 81
				13 01 00 00 00 00 02 AF 03
				13 01 00 00 00 00 02 B0 B4
				13 01 00 00 00 00 02 B1 03
				13 01 00 00 00 00 02 B2 D3
				13 01 00 00 00 00 02 B3 00
				13 01 00 00 00 00 02 B4 00
				13 01 00 00 00 00 02 B5 00
				13 01 00 00 00 00 02 B6 03
				13 01 00 00 00 00 02 B7 00
				13 01 00 00 00 00 02 B8 0A
				13 01 00 00 00 00 02 B9 00
				13 01 00 00 00 00 02 BA 13
				13 01 00 00 00 00 02 BB 00
				13 01 00 00 00 00 02 BC 20
				13 01 00 00 00 00 02 BD 00
				13 01 00 00 00 00 02 BE 2E
				13 01 00 00 00 00 02 BF 00
				13 01 00 00 00 00 02 C0 3C
				13 01 00 00 00 00 02 C1 00
				13 01 00 00 00 00 02 C2 47
				13 01 00 00 00 00 02 C3 00
				13 01 00 00 00 00 02 C4 52
				13 01 00 00 00 00 02 C5 00
				13 01 00 00 00 00 02 C6 8E
				13 01 00 00 00 00 02 C7 00
				13 01 00 00 00 00 02 C8 B8
				13 01 00 00 00 00 02 C9 01
				13 01 00 00 00 00 02 CA 01
				13 01 00 00 00 00 02 CB 01
				13 01 00 00 00 00 02 CC 3A
				13 01 00 00 00 00 02 CD 01
				13 01 00 00 00 00 02 CE 7E
				13 01 00 00 00 00 02 CF 01
				13 01 00 00 00 00 02 D0 B2
				13 01 00 00 00 00 02 D1 01
				13 01 00 00 00 00 02 D2 B4
				13 01 00 00 00 00 02 D3 01
				13 01 00 00 00 00 02 D4 E8
				13 01 00 00 00 00 02 D5 02
				13 01 00 00 00 00 02 D6 18
				13 01 00 00 00 00 02 D7 02
				13 01 00 00 00 00 02 D8 36
				13 01 00 00 00 00 02 D9 02
				13 01 00 00 00 00 02 DA 5C
				13 01 00 00 00 00 02 DB 02
				13 01 00 00 00 00 02 DC 93
				13 01 00 00 00 00 02 DD 02
				13 01 00 00 00 00 02 DE E1
				13 01 00 00 00 00 02 DF 02
				13 01 00 00 00 00 02 E0 E4
				13 01 00 00 00 00 02 E1 02
				13 01 00 00 00 00 02 E2 E8
				13 01 00 00 00 00 02 E3 02
				13 01 00 00 00 00 02 E4 EC
				13 01 00 00 00 00 02 E5 03
				13 01 00 00 00 00 02 E6 09
				13 01 00 00 00 00 02 E7 03
				13 01 00 00 00 00 02 E8 49
				13 01 00 00 00 00 02 E9 03
				13 01 00 00 00 00 02 EA 81
				13 01 00 00 00 00 02 EB 03
				13 01 00 00 00 00 02 EC B4
				13 01 00 00 00 00 02 ED 03
				13 01 00 00 00 00 02 EE D3
				13 01 00 00 00 00 02 EF 00
				13 01 00 00 00 00 02 F0 00
				13 01 00 00 00 00 02 F1 00
				13 01 00 00 00 00 02 F2 17
				13 01 00 00 00 00 02 F3 00
				13 01 00 00 00 00 02 F4 3D
				13 01 00 00 00 00 02 F5 00
				13 01 00 00 00 00 02 F6 5C
				13 01 00 00 00 00 02 F7 00
				13 01 00 00 00 00 02 F8 79
				13 01 00 00 00 00 02 F9 00
				13 01 00 00 00 00 02 FA 92
				13 01 00 00 00 00 02 FF 02
				13 01 00 00 00 00 02 FB 01
				13 01 00 00 00 00 02 00 00
				13 01 00 00 00 00 02 01 A8
				13 01 00 00 00 00 02 02 00
				13 01 00 00 00 00 02 03 B9
				13 01 00 00 00 00 02 04 00
				13 01 00 00 00 00 02 05 CB
				13 01 00 00 00 00 02 06 00
				13 01 00 00 00 00 02 07 FF
				13 01 00 00 00 00 02 08 01
				13 01 00 00 00 00 02 09 24
				13 01 00 00 00 00 02 0A 01
				13 01 00 00 00 00 02 0B 55
				13 01 00 00 00 00 02 0C 01
				13 01 00 00 00 00 02 0D 7B
				13 01 00 00 00 00 02 0E 01
				13 01 00 00 00 00 02 0F AB
				13 01 00 00 00 00 02 10 01
				13 01 00 00 00 00 02 11 D6
				13 01 00 00 00 00 02 12 01
				13 01 00 00 00 00 02 13 D7
				13 01 00 00 00 00 02 14 02
				13 01 00 00 00 00 02 15 01
				13 01 00 00 00 00 02 16 02
				13 01 00 00 00 00 02 17 2A
				13 01 00 00 00 00 02 18 02
				13 01 00 00 00 00 02 19 45
				13 01 00 00 00 00 02 1A 02
				13 01 00 00 00 00 02 1B 68
				13 01 00 00 00 00 02 1C 02
				13 01 00 00 00 00 02 1D 92
				13 01 00 00 00 00 02 1E 02
				13 01 00 00 00 00 02 1F CE
				13 01 00 00 00 00 02 20 02
				13 01 00 00 00 00 02 21 D0
				13 01 00 00 00 00 02 22 02
				13 01 00 00 00 00 02 23 D1
				13 01 00 00 00 00 02 24 02
				13 01 00 00 00 00 02 25 D3
				13 01 00 00 00 00 02 26 02
				13 01 00 00 00 00 02 27 E6
				13 01 00 00 00 00 02 28 03
				13 01 00 00 00 00 02 29 10
				13 01 00 00 00 00 02 2A 03
				13 01 00 00 00 00 02 2B 48
				13 01 00 00 00 00 02 2D 03
				13 01 00 00 00 00 02 2F 9E
				13 01 00 00 00 00 02 30 03
				13 01 00 00 00 00 02 31 D3
				13 01 00 00 00 00 02 32 00
				13 01 00 00 00 00 02 33 00
				13 01 00 00 00 00 02 34 00
				13 01 00 00 00 00 02 35 17
				13 01 00 00 00 00 02 36 00
				13 01 00 00 00 00 02 37 3D
				13 01 00 00 00 00 02 38 00
				13 01 00 00 00 00 02 39 5C
				13 01 00 00 00 00 02 3A 00
				13 01 00 00 00 00 02 3B 79
				13 01 00 00 00 00 02 3D 00
				13 01 00 00 00 00 02 3F 92
				13 01 00 00 00 00 02 40 00
				13 01 00 00 00 00 02 41 A8
				13 01 00 00 00 00 02 42 00
				13 01 00 00 00 00 02 43 B9
				13 01 00 00 00 00 02 44 00
				13 01 00 00 00 00 02 45 CB
				13 01 00 00 00 00 02 46 00
				13 01 00 00 00 00 02 47 FF
				13 01 00 00 00 00 02 48 01
				13 01 00 00 00 00 02 49 24
				13 01 00 00 00 00 02 4A 01
				13 01 00 00 00 00 02 4B 55
				13 01 00 00 00 00 02 4C 01
				13 01 00 00 00 00 02 4D 7B
				13 01 00 00 00 00 02 4E 01
				13 01 00 00 00 00 02 4F AB
				13 01 00 00 00 00 02 50 01
				13 01 00 00 00 00 02 51 D6
				13 01 00 00 00 00 02 52 01
				13 01 00 00 00 00 02 53 D7
				13 01 00 00 00 00 02 54 02
				13 01 00 00 00 00 02 55 01
				13 01 00 00 00 00 02 56 02
				13 01 00 00 00 00 02 58 2A
				13 01 00 00 00 00 02 59 02
				13 01 00 00 00 00 02 5A 45
				13 01 00 00 00 00 02 5B 02
				13 01 00 00 00 00 02 5C 68
				13 01 00 00 00 00 02 5D 02
				13 01 00 00 00 00 02 5E 92
				13 01 00 00 00 00 02 5F 02
				13 01 00 00 00 00 02 60 CE
				13 01 00 00 00 00 02 61 02
				13 01 00 00 00 00 02 62 D0
				13 01 00 00 00 00 02 63 02
				13 01 00 00 00 00 02 64 D1
				13 01 00 00 00 00 02 65 02
				13 01 00 00 00 00 02 66 D3
				13 01 00 00 00 00 02 67 02
				13 01 00 00 00 00 02 68 E6
				13 01 00 00 00 00 02 69 03
				13 01 00 00 00 00 02 6A 10
				13 01 00 00 00 00 02 6B 03
				13 01 00 00 00 00 02 6C 48
				13 01 00 00 00 00 02 6D 03
				13 01 00 00 00 00 02 6E 9E
				13 01 00 00 00 00 02 6F 03
				13 01 00 00 00 00 02 70 D3
				13 01 00 00 00 00 02 71 00
				13 01 00 00 00 00 02 72 00
				13 01 00 00 00 00 02 73 00
				13 01 00 00 00 00 02 74 34
				13 01 00 00 00 00 02 75 00
				13 01 00 00 00 00 02 76 8A
				13 01 00 00 00 00 02 77 00
				13 01 00 00 00 00 02 78 BF
				13 01 00 00 00 00 02 79 00
				13 01 00 00 00 00 02 7A E2
				13 01 00 00 00 00 02 7B 00
				13 01 00 00 00 00 02 7C FB
				13 01 00 00 00 00 02 7D 01
				13 01 00 00 00 00 02 7E 0B
				13 01 00 00 00 00 02 7F 01
				13 01 00 00 00 00 02 80 17
				13 01 00 00 00 00 02 81 01
				13 01 00 00 00 00 02 82 24
				13 01 00 00 00 00 02 83 01
				13 01 00 00 00 00 02 84 4A
				13 01 00 00 00 00 02 85 01
				13 01 00 00 00 00 02 86 64
				13 01 00 00 00 00 02 87 01
				13 01 00 00 00 00 02 88 8C
				13 01 00 00 00 00 02 89 01
				13 01 00 00 00 00 02 8A AC
				13 01 00 00 00 00 02 8B 01
				13 01 00 00 00 00 02 8C D4
				13 01 00 00 00 00 02 8D 01
				13 01 00 00 00 00 02 8E F5
				13 01 00 00 00 00 02 8F 01
				13 01 00 00 00 00 02 90 F6
				13 01 00 00 00 00 02 91 02
				13 01 00 00 00 00 02 92 18
				13 01 00 00 00 00 02 93 02
				13 01 00 00 00 00 02 94 3B
				13 01 00 00 00 00 02 95 02
				13 01 00 00 00 00 02 96 55
				13 01 00 00 00 00 02 97 02
				13 01 00 00 00 00 02 98 75
				13 01 00 00 00 00 02 99 02
				13 01 00 00 00 00 02 9A 9F
				13 01 00 00 00 00 02 9B 02
				13 01 00 00 00 00 02 9C DB
				13 01 00 00 00 00 02 9D 02
				13 01 00 00 00 00 02 9E DE
				13 01 00 00 00 00 02 9F 02
				13 01 00 00 00 00 02 A0 E1
				13 01 00 00 00 00 02 A2 02
				13 01 00 00 00 00 02 A3 E5
				13 01 00 00 00 00 02 A4 02
				13 01 00 00 00 00 02 A5 F4
				13 01 00 00 00 00 02 A6 03
				13 01 00 00 00 00 02 A7 11
				13 01 00 00 00 00 02 A9 03
				13 01 00 00 00 00 02 AA 43
				13 01 00 00 00 00 02 AB 03
				13 01 00 00 00 00 02 AC 9C
				13 01 00 00 00 00 02 AD 03
				13 01 00 00 00 00 02 AE D3
				13 01 00 00 00 00 02 AF 00
				13 01 00 00 00 00 02 B0 00
				13 01 00 00 00 00 02 B1 00
				13 01 00 00 00 00 02 B2 34
				13 01 00 00 00 00 02 B3 00
				13 01 00 00 00 00 02 B4 8A
				13 01 00 00 00 00 02 B5 00
				13 01 00 00 00 00 02 B6 BF
				13 01 00 00 00 00 02 B7 00
				13 01 00 00 00 00 02 B8 E2
				13 01 00 00 00 00 02 B9 00
				13 01 00 00 00 00 02 BA FB
				13 01 00 00 00 00 02 BB 01
				13 01 00 00 00 00 02 BC 0B
				13 01 00 00 00 00 02 BD 01
				13 01 00 00 00 00 02 BE 17
				13 01 00 00 00 00 02 BF 01
				13 01 00 00 00 00 02 C0 24
				13 01 00 00 00 00 02 C1 01
				13 01 00 00 00 00 02 C2 4A
				13 01 00 00 00 00 02 C3 01
				13 01 00 00 00 00 02 C4 64
				13 01 00 00 00 00 02 C5 01
				13 01 00 00 00 00 02 C6 8C
				13 01 00 00 00 00 02 C7 01
				13 01 00 00 00 00 02 C8 AC
				13 01 00 00 00 00 02 C9 01
				13 01 00 00 00 00 02 CA D4
				13 01 00 00 00 00 02 CB 01
				13 01 00 00 00 00 02 CC F5
				13 01 00 00 00 00 02 CD 01
				13 01 00 00 00 00 02 CE F6
				13 01 00 00 00 00 02 CF 02
				13 01 00 00 00 00 02 D0 18
				13 01 00 00 00 00 02 D1 02
				13 01 00 00 00 00 02 D2 3B
				13 01 00 00 00 00 02 D3 02
				13 01 00 00 00 00 02 D4 55
				13 01 00 00 00 00 02 D5 02
				13 01 00 00 00 00 02 D6 75
				13 01 00 00 00 00 02 D7 02
				13 01 00 00 00 00 02 D8 9F
				13 01 00 00 00 00 02 D9 02
				13 01 00 00 00 00 02 DA DB
				13 01 00 00 00 00 02 DB 02
				13 01 00 00 00 00 02 DC DE
				13 01 00 00 00 00 02 DD 02
				13 01 00 00 00 00 02 DE E1
				13 01 00 00 00 00 02 DF 02
				13 01 00 00 00 00 02 E0 E5
				13 01 00 00 00 00 02 E1 02
				13 01 00 00 00 00 02 E2 F4
				13 01 00 00 00 00 02 E3 03
				13 01 00 00 00 00 02 E4 11
				13 01 00 00 00 00 02 E5 03
				13 01 00 00 00 00 02 E6 43
				13 01 00 00 00 00 02 E7 03
				13 01 00 00 00 00 02 E8 9C
				13 01 00 00 00 00 02 E9 03
				13 01 00 00 00 00 02 EA D3
				13 01 00 00 00 00 02 FF 00
				05 01 00 00 00 00 01 11];
		qcom,mdss-dsi-on-command = [05 01 00 00 00 00 01 29];
		qcom,mdss-dsi-off-command = [05 01 00 00 14 00 01 28
						05 01 00 00 50 00 01 10];
		qcom,mdss-dsi-on-command-state = "dsi_lp_mode";
		qcom,mdss-dsi-off-command-state = "dsi_hs_mode";

		somc,mdss-dsi-cabc-early-on-command = [15 01 00 00 00 00 02 FF 04
				15 01 00 00 00 00 02 08 05
				15 01 00 00 00 00 02 2A 84
				15 01 00 00 00 00 02 29 99
				15 01 00 00 00 00 02 28 99
				15 01 00 00 00 00 02 27 99
				15 01 00 00 00 00 02 26 AA
				15 01 00 00 00 00 02 25 BB
				15 01 00 00 00 00 02 24 CC
				15 01 00 00 00 00 02 23 DD
				15 01 00 00 00 00 02 22 EE
				15 01 00 00 00 00 02 21 FF
				15 01 00 00 00 00 02 33 0C
				15 01 00 00 00 00 02 FB 01
				15 01 00 00 00 00 02 FF 00
				15 01 00 00 00 00 02 51 FF
				15 01 00 00 00 00 02 53 2C
				15 01 00 00 00 00 02 55 03];
		somc,mdss-dsi-cabc-early-on-v3-command = [15 01 00 00 00 00 02 FF 04
				15 01 00 00 00 00 02 08 05
				15 01 00 00 00 00 02 2A 60
				15 01 00 00 00 00 02 29 6B
				15 01 00 00 00 00 02 28 75
				15 01 00 00 00 00 02 27 80
				15 01 00 00 00 00 02 26 90
				15 01 00 00 00 00 02 25 A0
				15 01 00 00 00 00 02 24 AF
				15 01 00 00 00 00 02 23 C7
				15 01 00 00 00 00 02 22 E0
				15 01 00 00 00 00 02 21 FF
				15 01 00 00 00 00 02 33 0C
				15 01 00 00 00 00 02 FB 01
				15 01 00 00 00 00 02 FF 00
				15 01 00 00 00 00 02 51 FF
				15 01 00 00 00 00 02 53 2C
				15 01 00 00 00 00 02 55 03];
		somc,mdss-dsi-cabc-late-off-command = [15 01 00 00 00 00 02 51 00
				15 01 00 00 00 00 02 53 00
				15 01 00 00 00 00 02 55 00];
		somc,mdss-dsi-cabc-enabled = <1>;

		qcom,mdss-dsi-h-sync-pulse = <1>;
		qcom,mdss-dsi-traffic-mode = "non_burst_sync_event";
		qcom,mdss-dsi-bllp-eof-power-mode;
		qcom,mdss-dsi-bllp-power-mode;
		qcom,mdss-dsi-lane-0-state;
		qcom,mdss-dsi-lane-1-state;
		qcom,mdss-dsi-lane-2-state;
		qcom,mdss-dsi-lane-3-state;
		qcom,mdss-dsi-panel-timings = [da 46 39 00 5f 56 3c 48 5d 03 04 00];
		qcom,mdss-dsi-t-clk-post = <0x20>;
		qcom,mdss-dsi-t-clk-pre = <0x2a>;
		qcom,mdss-dsi-bl-min-level = <1>;
		qcom,mdss-dsi-bl-max-level = <4095>;
		qcom,mdss-dsi-dma-trigger = "trigger_sw";
		qcom,mdss-dsi-mdp-trigger = "none";
		qcom,mdss-dsi-bl-pmic-control-type = "bl_ctrl_wled";
		qcom,mdss-dsi-pan-enable-dynamic-fps;
		qcom,mdss-dsi-pan-fps-update = "dfps_suspend_resume_mode";
		qcom,mdss-dsi-reset-sequence = <1 20>, <0 200>, <1 20>;

		somc,panel-id = [ff];
		somc,panel-detect = <1>;
		somc,driver-ic = <1>;
		somc,panel-id-read-cmds;
		qcom,mdss-pan-physical-width-dimension = <62>;
		qcom,mdss-pan-physical-height-dimension = <110>;
		somc,mdss-phy-size-mm = <62 110>;
		somc,mdss-dsi-lane-config = [00 c2 45 00 00 00 00 01 75
				00 c2 45 00 00 00 00 01 75
				00 c2 45 00 00 00 00 01 75
				00 c2 45 00 00 00 00 01 75
				00 02 45 00 00 00 00 01 97];
		somc,mdss-dsi-disp-on-in-hs = <1>;
		somc,mdss-dsi-wait-time-before-on-cmd = <120>;
		somc,mdss-dsi-init-from-begin = <1>;
		qcom,mdss-brightness-max-level = <255>;
		somc,disp-en-off-pre = <10>;
		somc,disp-en-off-post = <10>;
		somc,disp-en-on-pre = <200>;
		somc,disp-en-on-post = <10>;
		somc,pw-on-rst-seq = <1 10>, <0 10>, <1 25>;
		somc,pw-off-rst-seq = <0 10>;
	};

	dsi_novatek_jdc_1080_vid: somc,novatek_jdc_1080p_panel {
		compatible = "qcom,mdss-dsi-panel";

		qcom,mdss-dsi-panel-name = "jdc novatek 1080p video";
		qcom,mdss-dsi-panel-controller = <&mdss_dsi0>;
		qcom,mdss-dsi-panel-type = "dsi_video_mode";
		qcom,mdss-dsi-panel-destination = "display_1";
		qcom,mdss-dsi-panel-framerate = <60>;
		qcom,mdss-dsi-virtual-channel-id = <0>;
		qcom,mdss-dsi-stream = <0>;
		qcom,mdss-dsi-panel-width = <1080>;
		qcom,mdss-dsi-panel-height = <1920>;
		qcom,mdss-dsi-h-front-porch = <128>;
		qcom,mdss-dsi-h-back-porch = <72>;
		qcom,mdss-dsi-h-pulse-width = <8>;
		qcom,mdss-dsi-h-sync-skew = <0>;
		qcom,mdss-dsi-v-back-porch = <4>;
		qcom,mdss-dsi-v-front-porch = <8>;
		qcom,mdss-dsi-v-pulse-width = <4>;
		qcom,mdss-dsi-h-left-border = <0>;
		qcom,mdss-dsi-h-right-border = <0>;
		qcom,mdss-dsi-v-top-border = <0>;
		qcom,mdss-dsi-v-bottom-border = <0>;
		qcom,mdss-dsi-bpp = <24>;
		qcom,mdss-dsi-underflow-color = <0x0>;
		qcom,mdss-dsi-border-color = <0>;
		somc,mdss-dsi-id-read-command = [06 01 00 01 05 00 02 A1 00];
		somc,mdss-dsi-init-command = [
				15 01 00 00 00 00 02 36 00
				15 01 00 00 00 00 02 D3 08
				15 01 00 00 00 00 02 D4 08
				15 01 00 00 00 00 02 D5 50
				15 01 00 00 00 00 02 D6 81
				13 01 00 00 00 00 02 FF 01
				13 01 00 00 00 00 02 FB 01
				13 01 00 00 00 00 02 75 00
				13 01 00 00 00 00 02 76 00
				13 01 00 00 00 00 02 77 00
				13 01 00 00 00 00 02 78 03
				13 01 00 00 00 00 02 79 00
				13 01 00 00 00 00 02 7A 0A
				13 01 00 00 00 00 02 7B 00
				13 01 00 00 00 00 02 7C 13
				13 01 00 00 00 00 02 7D 00
				13 01 00 00 00 00 02 7E 20
				13 01 00 00 00 00 02 7F 00
				13 01 00 00 00 00 02 80 2E
				13 01 00 00 00 00 02 81 00
				13 01 00 00 00 00 02 82 3C
				13 01 00 00 00 00 02 83 00
				13 01 00 00 00 00 02 84 47
				13 01 00 00 00 00 02 85 00
				13 01 00 00 00 00 02 86 52
				13 01 00 00 00 00 02 87 00
				13 01 00 00 00 00 02 88 8E
				13 01 00 00 00 00 02 89 00
				13 01 00 00 00 00 02 8A B8
				13 01 00 00 00 00 02 8B 01
				13 01 00 00 00 00 02 8C 01
				13 01 00 00 00 00 02 8D 01
				13 01 00 00 00 00 02 8E 3A
				13 01 00 00 00 00 02 8F 01
				13 01 00 00 00 00 02 90 7E
				13 01 00 00 00 00 02 91 01
				13 01 00 00 00 00 02 92 B2
				13 01 00 00 00 00 02 93 01
				13 01 00 00 00 00 02 94 B4
				13 01 00 00 00 00 02 95 01
				13 01 00 00 00 00 02 96 E8
				13 01 00 00 00 00 02 97 02
				13 01 00 00 00 00 02 98 18
				13 01 00 00 00 00 02 99 02
				13 01 00 00 00 00 02 9A 36
				13 01 00 00 00 00 02 9B 02
				13 01 00 00 00 00 02 9C 5C
				13 01 00 00 00 00 02 9D 02
				13 01 00 00 00 00 02 9E 93
				13 01 00 00 00 00 02 9F 02
				13 01 00 00 00 00 02 A0 E1
				13 01 00 00 00 00 02 A2 02
				13 01 00 00 00 00 02 A3 E4
				13 01 00 00 00 00 02 A4 02
				13 01 00 00 00 00 02 A5 E8
				13 01 00 00 00 00 02 A6 02
				13 01 00 00 00 00 02 A7 EC
				13 01 00 00 00 00 02 A9 03
				13 01 00 00 00 00 02 AA 09
				13 01 00 00 00 00 02 AB 03
				13 01 00 00 00 00 02 AC 49
				13 01 00 00 00 00 02 AD 03
				13 01 00 00 00 00 02 AE 81
				13 01 00 00 00 00 02 AF 03
				13 01 00 00 00 00 02 B0 B4
				13 01 00 00 00 00 02 B1 03
				13 01 00 00 00 00 02 B2 D3
				13 01 00 00 00 00 02 B3 00
				13 01 00 00 00 00 02 B4 00
				13 01 00 00 00 00 02 B5 00
				13 01 00 00 00 00 02 B6 03
				13 01 00 00 00 00 02 B7 00
				13 01 00 00 00 00 02 B8 0A
				13 01 00 00 00 00 02 B9 00
				13 01 00 00 00 00 02 BA 13
				13 01 00 00 00 00 02 BB 00
				13 01 00 00 00 00 02 BC 20
				13 01 00 00 00 00 02 BD 00
				13 01 00 00 00 00 02 BE 2E
				13 01 00 00 00 00 02 BF 00
				13 01 00 00 00 00 02 C0 3C
				13 01 00 00 00 00 02 C1 00
				13 01 00 00 00 00 02 C2 47
				13 01 00 00 00 00 02 C3 00
				13 01 00 00 00 00 02 C4 52
				13 01 00 00 00 00 02 C5 00
				13 01 00 00 00 00 02 C6 8E
				13 01 00 00 00 00 02 C7 00
				13 01 00 00 00 00 02 C8 B8
				13 01 00 00 00 00 02 C9 01
				13 01 00 00 00 00 02 CA 01
				13 01 00 00 00 00 02 CB 01
				13 01 00 00 00 00 02 CC 3A
				13 01 00 00 00 00 02 CD 01
				13 01 00 00 00 00 02 CE 7E
				13 01 00 00 00 00 02 CF 01
				13 01 00 00 00 00 02 D0 B2
				13 01 00 00 00 00 02 D1 01
				13 01 00 00 00 00 02 D2 B4
				13 01 00 00 00 00 02 D3 01
				13 01 00 00 00 00 02 D4 E8
				13 01 00 00 00 00 02 D5 02
				13 01 00 00 00 00 02 D6 18
				13 01 00 00 00 00 02 D7 02
				13 01 00 00 00 00 02 D8 36
				13 01 00 00 00 00 02 D9 02
				13 01 00 00 00 00 02 DA 5C
				13 01 00 00 00 00 02 DB 02
				13 01 00 00 00 00 02 DC 93
				13 01 00 00 00 00 02 DD 02
				13 01 00 00 00 00 02 DE E1
				13 01 00 00 00 00 02 DF 02
				13 01 00 00 00 00 02 E0 E4
				13 01 00 00 00 00 02 E1 02
				13 01 00 00 00 00 02 E2 E8
				13 01 00 00 00 00 02 E3 02
				13 01 00 00 00 00 02 E4 EC
				13 01 00 00 00 00 02 E5 03
				13 01 00 00 00 00 02 E6 09
				13 01 00 00 00 00 02 E7 03
				13 01 00 00 00 00 02 E8 49
				13 01 00 00 00 00 02 E9 03
				13 01 00 00 00 00 02 EA 81
				13 01 00 00 00 00 02 EB 03
				13 01 00 00 00 00 02 EC B4
				13 01 00 00 00 00 02 ED 03
				13 01 00 00 00 00 02 EE D3
				13 01 00 00 00 00 02 EF 00
				13 01 00 00 00 00 02 F0 00
				13 01 00 00 00 00 02 F1 00
				13 01 00 00 00 00 02 F2 17
				13 01 00 00 00 00 02 F3 00
				13 01 00 00 00 00 02 F4 3D
				13 01 00 00 00 00 02 F5 00
				13 01 00 00 00 00 02 F6 5C
				13 01 00 00 00 00 02 F7 00
				13 01 00 00 00 00 02 F8 79
				13 01 00 00 00 00 02 F9 00
				13 01 00 00 00 00 02 FA 92
				13 01 00 00 00 00 02 FF 02
				13 01 00 00 00 00 02 FB 01
				13 01 00 00 00 00 02 00 00
				13 01 00 00 00 00 02 01 A8
				13 01 00 00 00 00 02 02 00
				13 01 00 00 00 00 02 03 B9
				13 01 00 00 00 00 02 04 00
				13 01 00 00 00 00 02 05 CB
				13 01 00 00 00 00 02 06 00
				13 01 00 00 00 00 02 07 FF
				13 01 00 00 00 00 02 08 01
				13 01 00 00 00 00 02 09 24
				13 01 00 00 00 00 02 0A 01
				13 01 00 00 00 00 02 0B 55
				13 01 00 00 00 00 02 0C 01
				13 01 00 00 00 00 02 0D 7B
				13 01 00 00 00 00 02 0E 01
				13 01 00 00 00 00 02 0F AB
				13 01 00 00 00 00 02 10 01
				13 01 00 00 00 00 02 11 D6
				13 01 00 00 00 00 02 12 01
				13 01 00 00 00 00 02 13 D7
				13 01 00 00 00 00 02 14 02
				13 01 00 00 00 00 02 15 01
				13 01 00 00 00 00 02 16 02
				13 01 00 00 00 00 02 17 2A
				13 01 00 00 00 00 02 18 02
				13 01 00 00 00 00 02 19 45
				13 01 00 00 00 00 02 1A 02
				13 01 00 00 00 00 02 1B 68
				13 01 00 00 00 00 02 1C 02
				13 01 00 00 00 00 02 1D 92
				13 01 00 00 00 00 02 1E 02
				13 01 00 00 00 00 02 1F CE
				13 01 00 00 00 00 02 20 02
				13 01 00 00 00 00 02 21 D0
				13 01 00 00 00 00 02 22 02
				13 01 00 00 00 00 02 23 D1
				13 01 00 00 00 00 02 24 02
				13 01 00 00 00 00 02 25 D3
				13 01 00 00 00 00 02 26 02
				13 01 00 00 00 00 02 27 E6
				13 01 00 00 00 00 02 28 03
				13 01 00 00 00 00 02 29 10
				13 01 00 00 00 00 02 2A 03
				13 01 00 00 00 00 02 2B 48
				13 01 00 00 00 00 02 2D 03
				13 01 00 00 00 00 02 2F 9E
				13 01 00 00 00 00 02 30 03
				13 01 00 00 00 00 02 31 D3
				13 01 00 00 00 00 02 32 00
				13 01 00 00 00 00 02 33 00
				13 01 00 00 00 00 02 34 00
				13 01 00 00 00 00 02 35 17
				13 01 00 00 00 00 02 36 00
				13 01 00 00 00 00 02 37 3D
				13 01 00 00 00 00 02 38 00
				13 01 00 00 00 00 02 39 5C
				13 01 00 00 00 00 02 3A 00
				13 01 00 00 00 00 02 3B 79
				13 01 00 00 00 00 02 3D 00
				13 01 00 00 00 00 02 3F 92
				13 01 00 00 00 00 02 40 00
				13 01 00 00 00 00 02 41 A8
				13 01 00 00 00 00 02 42 00
				13 01 00 00 00 00 02 43 B9
				13 01 00 00 00 00 02 44 00
				13 01 00 00 00 00 02 45 CB
				13 01 00 00 00 00 02 46 00
				13 01 00 00 00 00 02 47 FF
				13 01 00 00 00 00 02 48 01
				13 01 00 00 00 00 02 49 24
				13 01 00 00 00 00 02 4A 01
				13 01 00 00 00 00 02 4B 55
				13 01 00 00 00 00 02 4C 01
				13 01 00 00 00 00 02 4D 7B
				13 01 00 00 00 00 02 4E 01
				13 01 00 00 00 00 02 4F AB
				13 01 00 00 00 00 02 50 01
				13 01 00 00 00 00 02 51 D6
				13 01 00 00 00 00 02 52 01
				13 01 00 00 00 00 02 53 D7
				13 01 00 00 00 00 02 54 02
				13 01 00 00 00 00 02 55 01
				13 01 00 00 00 00 02 56 02
				13 01 00 00 00 00 02 58 2A
				13 01 00 00 00 00 02 59 02
				13 01 00 00 00 00 02 5A 45
				13 01 00 00 00 00 02 5B 02
				13 01 00 00 00 00 02 5C 68
				13 01 00 00 00 00 02 5D 02
				13 01 00 00 00 00 02 5E 92
				13 01 00 00 00 00 02 5F 02
				13 01 00 00 00 00 02 60 CE
				13 01 00 00 00 00 02 61 02
				13 01 00 00 00 00 02 62 D0
				13 01 00 00 00 00 02 63 02
				13 01 00 00 00 00 02 64 D1
				13 01 00 00 00 00 02 65 02
				13 01 00 00 00 00 02 66 D3
				13 01 00 00 00 00 02 67 02
				13 01 00 00 00 00 02 68 E6
				13 01 00 00 00 00 02 69 03
				13 01 00 00 00 00 02 6A 10
				13 01 00 00 00 00 02 6B 03
				13 01 00 00 00 00 02 6C 48
				13 01 00 00 00 00 02 6D 03
				13 01 00 00 00 00 02 6E 9E
				13 01 00 00 00 00 02 6F 03
				13 01 00 00 00 00 02 70 D3
				13 01 00 00 00 00 02 71 00
				13 01 00 00 00 00 02 72 00
				13 01 00 00 00 00 02 73 00
				13 01 00 00 00 00 02 74 34
				13 01 00 00 00 00 02 75 00
				13 01 00 00 00 00 02 76 8A
				13 01 00 00 00 00 02 77 00
				13 01 00 00 00 00 02 78 BF
				13 01 00 00 00 00 02 79 00
				13 01 00 00 00 00 02 7A E2
				13 01 00 00 00 00 02 7B 00
				13 01 00 00 00 00 02 7C FB
				13 01 00 00 00 00 02 7D 01
				13 01 00 00 00 00 02 7E 0B
				13 01 00 00 00 00 02 7F 01
				13 01 00 00 00 00 02 80 17
				13 01 00 00 00 00 02 81 01
				13 01 00 00 00 00 02 82 24
				13 01 00 00 00 00 02 83 01
				13 01 00 00 00 00 02 84 4A
				13 01 00 00 00 00 02 85 01
				13 01 00 00 00 00 02 86 64
				13 01 00 00 00 00 02 87 01
				13 01 00 00 00 00 02 88 8C
				13 01 00 00 00 00 02 89 01
				13 01 00 00 00 00 02 8A AC
				13 01 00 00 00 00 02 8B 01
				13 01 00 00 00 00 02 8C D4
				13 01 00 00 00 00 02 8D 01
				13 01 00 00 00 00 02 8E F5
				13 01 00 00 00 00 02 8F 01
				13 01 00 00 00 00 02 90 F6
				13 01 00 00 00 00 02 91 02
				13 01 00 00 00 00 02 92 18
				13 01 00 00 00 00 02 93 02
				13 01 00 00 00 00 02 94 3B
				13 01 00 00 00 00 02 95 02
				13 01 00 00 00 00 02 96 55
				13 01 00 00 00 00 02 97 02
				13 01 00 00 00 00 02 98 75
				13 01 00 00 00 00 02 99 02
				13 01 00 00 00 00 02 9A 9F
				13 01 00 00 00 00 02 9B 02
				13 01 00 00 00 00 02 9C DB
				13 01 00 00 00 00 02 9D 02
				13 01 00 00 00 00 02 9E DE
				13 01 00 00 00 00 02 9F 02
				13 01 00 00 00 00 02 A0 E1
				13 01 00 00 00 00 02 A2 02
				13 01 00 00 00 00 02 A3 E5
				13 01 00 00 00 00 02 A4 02
				13 01 00 00 00 00 02 A5 F4
				13 01 00 00 00 00 02 A6 03
				13 01 00 00 00 00 02 A7 11
				13 01 00 00 00 00 02 A9 03
				13 01 00 00 00 00 02 AA 43
				13 01 00 00 00 00 02 AB 03
				13 01 00 00 00 00 02 AC 9C
				13 01 00 00 00 00 02 AD 03
				13 01 00 00 00 00 02 AE D3
				13 01 00 00 00 00 02 AF 00
				13 01 00 00 00 00 02 B0 00
				13 01 00 00 00 00 02 B1 00
				13 01 00 00 00 00 02 B2 34
				13 01 00 00 00 00 02 B3 00
				13 01 00 00 00 00 02 B4 8A
				13 01 00 00 00 00 02 B5 00
				13 01 00 00 00 00 02 B6 BF
				13 01 00 00 00 00 02 B7 00
				13 01 00 00 00 00 02 B8 E2
				13 01 00 00 00 00 02 B9 00
				13 01 00 00 00 00 02 BA FB
				13 01 00 00 00 00 02 BB 01
				13 01 00 00 00 00 02 BC 0B
				13 01 00 00 00 00 02 BD 01
				13 01 00 00 00 00 02 BE 17
				13 01 00 00 00 00 02 BF 01
				13 01 00 00 00 00 02 C0 24
				13 01 00 00 00 00 02 C1 01
				13 01 00 00 00 00 02 C2 4A
				13 01 00 00 00 00 02 C3 01
				13 01 00 00 00 00 02 C4 64
				13 01 00 00 00 00 02 C5 01
				13 01 00 00 00 00 02 C6 8C
				13 01 00 00 00 00 02 C7 01
				13 01 00 00 00 00 02 C8 AC
				13 01 00 00 00 00 02 C9 01
				13 01 00 00 00 00 02 CA D4
				13 01 00 00 00 00 02 CB 01
				13 01 00 00 00 00 02 CC F5
				13 01 00 00 00 00 02 CD 01
				13 01 00 00 00 00 02 CE F6
				13 01 00 00 00 00 02 CF 02
				13 01 00 00 00 00 02 D0 18
				13 01 00 00 00 00 02 D1 02
				13 01 00 00 00 00 02 D2 3B
				13 01 00 00 00 00 02 D3 02
				13 01 00 00 00 00 02 D4 55
				13 01 00 00 00 00 02 D5 02
				13 01 00 00 00 00 02 D6 75
				13 01 00 00 00 00 02 D7 02
				13 01 00 00 00 00 02 D8 9F
				13 01 00 00 00 00 02 D9 02
				13 01 00 00 00 00 02 DA DB
				13 01 00 00 00 00 02 DB 02
				13 01 00 00 00 00 02 DC DE
				13 01 00 00 00 00 02 DD 02
				13 01 00 00 00 00 02 DE E1
				13 01 00 00 00 00 02 DF 02
				13 01 00 00 00 00 02 E0 E5
				13 01 00 00 00 00 02 E1 02
				13 01 00 00 00 00 02 E2 F4
				13 01 00 00 00 00 02 E3 03
				13 01 00 00 00 00 02 E4 11
				13 01 00 00 00 00 02 E5 03
				13 01 00 00 00 00 02 E6 43
				13 01 00 00 00 00 02 E7 03
				13 01 00 00 00 00 02 E8 9C
				13 01 00 00 00 00 02 E9 03
				13 01 00 00 00 00 02 EA D3
				13 01 00 00 00 00 02 FF 00
				05 01 00 00 00 00 01 11];
		qcom,mdss-dsi-on-command = [05 01 00 00 00 00 01 29];
		qcom,mdss-dsi-off-command = [05 01 00 00 14 00 01 28
				05 01 00 00 50 00 01 10];
		qcom,mdss-dsi-on-command-state = "dsi_lp_mode";
		qcom,mdss-dsi-off-command-state = "dsi_hs_mode";

		somc,mdss-dsi-cabc-early-on-command = [15 01 00 00 00 00 02 FF 04
				15 01 00 00 00 00 02 08 05
				15 01 00 00 00 00 02 2A 84
				15 01 00 00 00 00 02 29 99
				15 01 00 00 00 00 02 28 99
				15 01 00 00 00 00 02 27 99
				15 01 00 00 00 00 02 26 AA
				15 01 00 00 00 00 02 25 BB
				15 01 00 00 00 00 02 24 CC
				15 01 00 00 00 00 02 23 DD
				15 01 00 00 00 00 02 22 EE
				15 01 00 00 00 00 02 21 FF
				15 01 00 00 00 00 02 33 0C
				15 01 00 00 00 00 02 FB 01
				15 01 00 00 00 00 02 FF 00
				15 01 00 00 00 00 02 51 FF
				15 01 00 00 00 00 02 53 2C
				15 01 00 00 00 00 02 55 03];
		somc,mdss-dsi-cabc-early-on-v3-command = [15 01 00 00 00 00 02 FF 04
				15 01 00 00 00 00 02 08 05
				15 01 00 00 00 00 02 2A 60
				15 01 00 00 00 00 02 29 6B
				15 01 00 00 00 00 02 28 75
				15 01 00 00 00 00 02 27 80
				15 01 00 00 00 00 02 26 90
				15 01 00 00 00 00 02 25 A0
				15 01 00 00 00 00 02 24 AF
				15 01 00 00 00 00 02 23 C7
				15 01 00 00 00 00 02 22 E0
				15 01 00 00 00 00 02 21 FF
				15 01 00 00 00 00 02 33 0C
				15 01 00 00 00 00 02 FB 01
				15 01 00 00 00 00 02 FF 00
				15 01 00 00 00 00 02 51 FF
				15 01 00 00 00 00 02 53 2C
				15 01 00 00 00 00 02 55 03];
		somc,mdss-dsi-cabc-late-off-command = [15 01 00 00 00 00 02 51 00
				15 01 00 00 00 00 02 53 00
				15 01 00 00 00 00 02 55 00];
		somc,mdss-dsi-cabc-enabled = <1>;

		qcom,mdss-dsi-h-sync-pulse = <1>;
		qcom,mdss-dsi-traffic-mode = "non_burst_sync_event";
		qcom,mdss-dsi-bllp-eof-power-mode;
		qcom,mdss-dsi-bllp-power-mode;
		qcom,mdss-dsi-lane-0-state;
		qcom,mdss-dsi-lane-1-state;
		qcom,mdss-dsi-lane-2-state;
		qcom,mdss-dsi-lane-3-state;
		qcom,mdss-dsi-panel-timings = [da 46 39 00 5f 56 3c 48 5d 03 04 00];
		qcom,mdss-dsi-t-clk-post = <0x20>;
		qcom,mdss-dsi-t-clk-pre = <0x2a>;
		qcom,mdss-dsi-bl-min-level = <1>;
		qcom,mdss-dsi-bl-max-level = <4095>;
		qcom,mdss-dsi-dma-trigger = "trigger_sw";
		qcom,mdss-dsi-mdp-trigger = "none";
		qcom,mdss-dsi-bl-pmic-control-type = "bl_ctrl_wled";
		qcom,mdss-dsi-pan-enable-dynamic-fps;
		qcom,mdss-dsi-pan-fps-update = "dfps_suspend_resume_mode";
		qcom,mdss-dsi-reset-sequence = <1 20>, <0 200>, <1 20>;

		somc,panel-id = [12 72 08 62];
		somc,driver-ic = <1>;
		qcom,mdss-pan-physical-width-dimension = <62>;
		qcom,mdss-pan-physical-height-dimension = <110>;
		somc,mdss-phy-size-mm = <62 110>;
		somc,mdss-dsi-lane-config = [00 c2 45 00 00 00 00 01 75
				00 c2 45 00 00 00 00 01 75
				00 c2 45 00 00 00 00 01 75
				00 c2 45 00 00 00 00 01 75
				00 02 45 00 00 00 00 01 97];
		somc,mdss-dsi-disp-on-in-hs = <1>;
		qcom,mdss-brightness-max-level = <255>;
		somc,disp-en-off-pre = <10>;
		somc,disp-en-off-post = <10>;
		somc,disp-en-on-pre = <200>;
		somc,disp-en-on-post = <10>;
		somc,pw-on-rst-seq = <1 10>, <0 10>, <1 25>;
		somc,pw-off-rst-seq = <0 10>;
		somc,mdss-dsi-wait-time-before-on-cmd = <120>;
		somc,mdss-dsi-init-from-begin = <1>;

		somc,mdss-dsi-uv-command = [04 01 00 00 00 00 01 DA
				04 01 00 00 00 00 01 DB];
		somc,mdss-dsi-uv-param-type = <2>;
		somc,mdss-dsi-pcc-table-size = <78>;
		somc,mdss-dsi-pcc-table = <
				0x00 0x01 0x26 0x29 0x38 0x3C 0x5FA9 0x7760 0x8000
				0x00 0x02 0x22 0x25 0x34 0x37 0x67BF 0x7988 0x8000
				0x00 0x03 0x26 0x29 0x34 0x37 0x67BF 0x7988 0x8000
				0x00 0x04 0x1F 0x22 0x30 0x33 0x6CCC 0x7AE1 0x8000
				0x00 0x05 0x23 0x26 0x30 0x33 0x6CCC 0x7AE1 0x8000
				0x00 0x06 0x27 0x2A 0x30 0x33 0x6CCC 0x7AE1 0x8000
				0x00 0x07 0x1C 0x1F 0x2C 0x2F 0x79EF 0x7E62 0x8000
				0x00 0x08 0x20 0x23 0x2C 0x2F 0x79EF 0x7E62 0x8000
				0x00 0x09 0x24 0x27 0x2C 0x2F 0x79EF 0x7E62 0x8000
				0x00 0x0A 0x28 0x2B 0x2C 0x2F 0x79EF 0x7E62 0x8000
				0x00 0x0B 0x1A 0x1D 0x28 0x2B 0x8000 0x8000 0x8000
				0x00 0x0C 0x1E 0x21 0x28 0x2B 0x8000 0x8000 0x8000
				0x00 0x0D 0x22 0x25 0x28 0x2B 0x8000 0x8000 0x8000
				0x00 0x0E 0x26 0x29 0x28 0x2B 0x8000 0x8000 0x8000
				0x00 0x0F 0x18 0x1B 0x24 0x27 0x7f00 0x7880 0x8000
				0x00 0x10 0x1C 0x1F 0x24 0x27 0x7980 0x7900 0x8000
				0x00 0x11 0x20 0x23 0x24 0x27 0x7500 0x7980 0x8000
				0x00 0x12 0x24 0x27 0x24 0x27 0x7000 0x7a00 0x8000
				0x00 0x13 0x28 0x29 0x24 0x27 0x6d00 0x7a80 0x8000
				0x00 0x14 0x16 0x17 0x20 0x23 0x8000 0x7500 0x7900
				0x00 0x15 0x18 0x1B 0x20 0x23 0x8000 0x7900 0x7d00
				0x00 0x16 0x1C 0x1F 0x20 0x23 0x7c00 0x7b80 0x7f00
				0x00 0x17 0x20 0x23 0x20 0x23 0x7200 0x7780 0x7980
				0x00 0x18 0x24 0x27 0x20 0x23 0x7100 0x7c00 0x7e00
				0x00 0x19 0x28 0x29 0x20 0x23 0x6f00 0x7d80 0x7f00
				0x00 0x1A 0x16 0x17 0x1C 0x1F 0x8000 0x7500 0x7600
				0x00 0x1B 0x18 0x1B 0x1C 0x1F 0x8000 0x7980 0x7a00
				0xFF 0x00 0x1C 0x1F 0x1C 0x1F 0x8000 0x8000 0x8000
				0x00 0x1C 0x20 0x23 0x1C 0x1F 0x7900 0x8000 0x7e80
				0x00 0x1D 0x24 0x27 0x1C 0x1F 0x7400 0x8000 0x7e00
				0x00 0x1E 0x28 0x29 0x1C 0x1F 0x7000 0x8000 0x7d80
				0x00 0x1F 0x16 0x17 0x18 0x1B 0x8000 0x7500 0x7280
				0x00 0x20 0x18 0x1B 0x18 0x1B 0x8000 0x7a00 0x7600
				0x00 0x21 0x1C 0x1F 0x18 0x1B 0x7e80 0x8000 0x7b80
				0x00 0x22 0x20 0x23 0x18 0x1B 0x7900 0x8000 0x7b00
				0x00 0x23 0x24 0x27 0x18 0x1B 0x7400 0x8000 0x7a00
				0x00 0x24 0x28 0x29 0x18 0x1B 0x7000 0x8000 0x7a00
				0x00 0x25 0x16 0x19 0x14 0x17 0x8000 0x7780 0x7000
				0x00 0x26 0x1A 0x1D 0x14 0x17 0x8000 0x7e00 0x7500
				0x00 0x27 0x1E 0x21 0x14 0x17 0x7b00 0x8000 0x7500
				0x00 0x28 0x22 0x25 0x14 0x17 0x7580 0x8000 0x7600
				0x00 0x29 0x16 0x19 0x10 0x13 0x8000 0x7900 0x6c80
				0x00 0x2A 0x1A 0x1D 0x10 0x13 0x8000 0x7f00 0x7200
				0x00 0x2B 0x1E 0x21 0x10 0x13 0x7a00 0x8000 0x7180
				0x00 0x2C 0x22 0x25 0x10 0x13 0x7500 0x8000 0x7200
				0x00 0x2D 0x16 0x19 0x0C 0x0F 0x8000 0x7900 0x6a00
				0x00 0x2E 0x1A 0x1D 0x0C 0x0F 0x8000 0x8000 0x6f00
				0x00 0x2F 0x1E 0x21 0x0C 0x0F 0x7980 0x8000 0x6e00
				0x00 0x30 0x16 0x19 0x08 0x0B 0x8000 0x7900 0x6800
				0x00 0x31 0x1A 0x1D 0x08 0x0B 0x8000 0x8000 0x6c00
				0x00 0x32 0x16 0x19 0x04 0x07 0x8000 0x7880 0x6580
				0x00 0x33 0x26 0x29 0x14 0x17 0x7580 0x8000 0x7600
				0x01 0x00 0x00 0x09 0x32 0x3C 0x8000 0x6D00 0x8000
				0x02 0x00 0x0A 0x13 0x32 0x3C 0x7A00 0x7100 0x8000
				0x03 0x00 0x14 0x1D 0x32 0x3C 0x7400 0x7180 0x8000
				0x04 0x00 0x1E 0x27 0x32 0x3C 0x7100 0x7200 0x8000
				0x05 0x00 0x28 0x31 0x32 0x3C 0x6C80 0x7180 0x8000
				0x06 0x00 0x32 0x3C 0x32 0x3C 0x6680 0x7300 0x8000
				0x07 0x00 0x00 0x09 0x28 0x31 0x8000 0x6B80 0x7080
				0x08 0x00 0x0A 0x13 0x28 0x31 0x8000 0x7400 0x8000
				0x09 0x00 0x14 0x1D 0x28 0x31 0x7A00 0x7700 0x8000
				0x0A 0x00 0x1E 0x27 0x28 0x31 0x7600 0x7780 0x8000
				0x0B 0x00 0x28 0x31 0x28 0x31 0x6F80 0x7980 0x8000
				0x0C 0x00 0x32 0x3C 0x28 0x31 0x7080 0x7E80 0x8000
				0x0D 0x00 0x00 0x09 0x14 0x27 0x8000 0x6B00 0x6D00
				0x0E 0x00 0x0A 0x13 0x14 0x27 0x8000 0x7380 0x7480
				0xFF 0x00 0x14 0x27 0x14 0x27 0x8000 0x8000 0x8000
				0x10 0x00 0x28 0x31 0x14 0x27 0x7500 0x8000 0x7E80
				0x11 0x00 0x32 0x3C 0x14 0x27 0x7100 0x8000 0x7C80
				0x12 0x00 0x00 0x09 0x00 0x09 0x8000 0x6900 0x6500
				0x13 0x00 0x00 0x13 0x0A 0x13 0x8000 0x7300 0x6F00
				0x13 0x00 0x0A 0x13 0x00 0x09 0x8000 0x7300 0x6F00
				0x14 0x00 0x14 0x27 0x0A 0x13 0x7F00 0x8000 0x7900
				0x15 0x00 0x14 0x27 0x00 0x09 0x7E80 0x8000 0x7680
				0x16 0x00 0x28 0x31 0x0A 0x13 0x7380 0x8000 0x7600
				0x17 0x00 0x32 0x3C 0x0A 0x13 0x7080 0x8000 0x7900
				0x18 0x00 0x28 0x31 0x00 0x09 0x7A00 0x8000 0x7580
				0x19 0x00 0x32 0x3C 0x00 0x09 0x6F00 0x8000 0x7200>;
	};
};
